VERSION ""

NS_ :

BS_:

BU_:

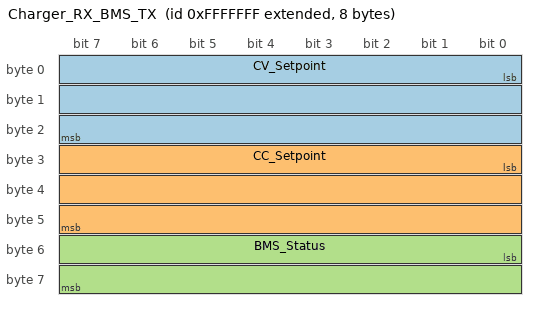
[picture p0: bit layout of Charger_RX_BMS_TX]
BO_ 2415919103 Charger_RX_BMS_TX: 8 Vector__XXX
	SG_ CV_Setpoint : 0|24@1+ (0.0001,0) [167.77216|600] "V" Vector__XXX
	SG_ CC_Setpoint : 24|24@1+ (0.000001,0) [5|7.5] "A" Vector__XXX
	SG_ BMS_Status : 48|16@1+ (1,0) [0|65535] "" Vector__XXX

BO_ 2164260864 Charger_Telemetry_1: 8 Vector__XXX
	SG_ V_IN_PFC_OUT : 0|32@1- (1,0) [0|0] "V" Vector__XXX
	SG_ V_OUT : 32|32@1- (1,0) [0|0] "V" Vector__XXX

BO_ 2181038080 Charger_Telemetry_2: 8 Vector__XXX
	SG_ I_OUT : 0|32@1- (1,0) [0|0] "A" Vector__XXX
	SG_ V_BATT : 32|32@1- (1,0) [0|0] "V" Vector__XXX

BO_ 2197815296 Charger_Telemetry_3: 8 Vector__XXX
	SG_ P_OUT : 0|32@1- (1,0) [0|0] "kW" Vector__XXX
	SG_ TEMP_1 : 32|32@1- (1,0) [0|0] "°C" Vector__XXX

BO_ 2214592512 Charger_Telemetry_4: 8 Vector__XXX
	SG_ TEMP_2 : 0|32@1- (1,0) [0|0] "°C" Vector__XXX
	SG_ TEMP_3 : 32|32@1- (1,0) [0|0] "°C" Vector__XXX

BO_ 2165309440 Charger_Status: 8 Vector__XXX
	SG_ STATE : 0|8@1+ (1,0) [0|0] "" Vector__XXX
	SG_ ERR_CODE : 8|8@1+ (1,0) [0|0] "" Vector__XXX

CM_ BO_ 2415919103 "Charger RX for setpoints/ status from BMS";
CM_ SG_ 2415919103 CV_Setpoint "Constant voltage setpoint";
CM_ SG_ 2415919103 CC_Setpoint "Constant current setpoint";
CM_ SG_ 2415919103 BMS_Status "BMS status (0 is normal)";
CM_ BO_ 2164260864 "V_IN, V_OUT";
CM_ BO_ 2181038080 "I_OUT, V_BATT";
CM_ BO_ 2197815296 "P_OUT, TEMP_1";
CM_ BO_ 2214592512 "TEMP_2, TEMP_3";
CM_ BO_ 2165309440 "STATE, ERR_CODE";
BA_DEF_ SG_  "SPN" INT 0 524287;
BA_DEF_ BO_  "VFrameFormat" ENUM  "StandardCAN","ExtendedCAN","reserved","J1939PG";
BA_DEF_  "DatabaseVersion" STRING ;
BA_DEF_  "BusType" STRING ;
BA_DEF_  "ProtocolType" STRING ;
BA_DEF_  "DatabaseCompiler" STRING ;
BA_DEF_DEF_  "SPN" 0;
BA_DEF_DEF_  "VFrameFormat" "J1939PG";
BA_DEF_DEF_  "DatabaseVersion" "DEMO PLUS";
BA_DEF_DEF_  "BusType" "";
BA_DEF_DEF_  "ProtocolType" "";
BA_DEF_DEF_  "DatabaseCompiler" "";
BA_ "BusType" "CAN";
BA_ "DatabaseCompiler" "CSS ELECTRONICS (WWW.CSSELECTRONICS.COM)";
BA_ "DatabaseVersion" "1.0.0";
BA_ "SPN" SG_ 2415919103 CV_Setpoint 190;
SIG_VALTYPE_ 2164260864 V_IN_PFC_OUT : 1;
SIG_VALTYPE_ 2181038080 I_OUT : 1;
SIG_VALTYPE_ 2197815296 P_OUT : 1;
SIG_VALTYPE_ 2214592512 TEMP_2 : 1;
SIG_VALTYPE_ 2164260864 V_OUT : 1;
SIG_VALTYPE_ 2181038080 V_BATT : 1;
SIG_VALTYPE_ 2197815296 TEMP_1 : 1;
SIG_VALTYPE_ 2214592512 TEMP_3 : 1;
